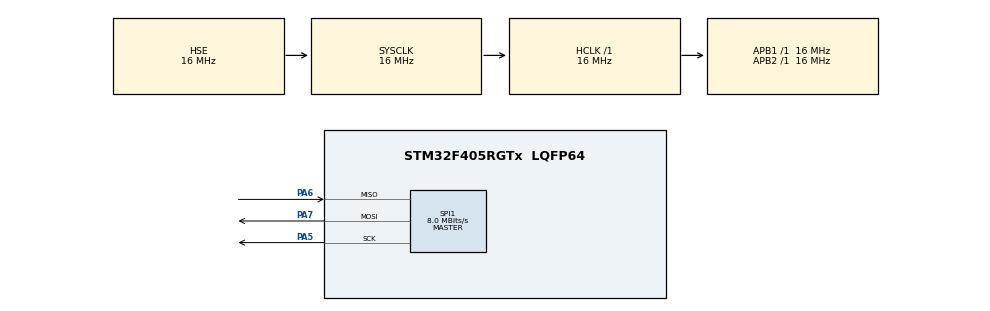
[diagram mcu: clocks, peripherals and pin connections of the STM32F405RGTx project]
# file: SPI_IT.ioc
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Mcu.Family=STM32F4
Mcu.Name=STM32F405RGTx
Mcu.Package=LQFP64
NVIC.PriorityGroup=NVIC_PRIORITYGROUP_4
NVIC.SPI1_IRQn=true\:0\:0\:false\:false\:true\:true\:true\:true
PA13.Mode=Serial_Wire
PA13.Signal=SYS_JTMS-SWDIO
PA14.Mode=Serial_Wire
PA14.Signal=SYS_JTCK-SWCLK
PA5.Mode=Full_Duplex_Master
PA5.Signal=SPI1_SCK
PA6.Mode=Full_Duplex_Master
PA6.Signal=SPI1_MISO
PA7.Mode=Full_Duplex_Master
PA7.Signal=SPI1_MOSI
PH0-OSC_IN.Mode=HSE-External-Oscillator
PH0-OSC_IN.Signal=RCC_OSC_IN
PH1-OSC_OUT.Mode=HSE-External-Oscillator
PH1-OSC_OUT.Signal=RCC_OSC_OUT
ProjectManager.HeapSize=0x200
ProjectManager.StackSize=0x400
ProjectManager.TargetToolchain=MDK-ARM V5.32
RCC.48MHZClocksFreq_Value=48000000
RCC.AHBFreq_Value=16000000
RCC.APB1Freq_Value=16000000
RCC.APB1TimFreq_Value=16000000
RCC.APB2Freq_Value=16000000
RCC.APB2TimFreq_Value=16000000
RCC.CortexFreq_Value=16000000
RCC.HCLKFreq_Value=16000000
RCC.HSE_VALUE=16000000
RCC.HSI_VALUE=16000000
RCC.LSE_VALUE=32768
RCC.PLLSourceVirtual=RCC_PLLSOURCE_HSE
RCC.SYSCLKFreq_VALUE=16000000
RCC.SYSCLKSource=RCC_SYSCLKSOURCE_HSE
RCC.VCOOutputFreq_Value=192000000
SPI1.CalculateBaudRate=8.0 MBits/s
SPI1.Direction=SPI_DIRECTION_2LINES
SPI1.Mode=SPI_MODE_MASTER
SPI1.VirtualType=VM_MASTER
board=custom

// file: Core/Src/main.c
/* USER CODE BEGIN Header */
/**
  ******************************************************************************
  * @file           : main.c
  * @brief          : Main program body
  ******************************************************************************
  * @attention
  *
  * Copyright (c) 2023 STMicroelectronics.
  * All rights reserved.
  *
  * This software is licensed under terms that can be found in the LICENSE file
  * in the root directory of this software component.
  * If no LICENSE file comes with this software, it is provided AS-IS.
  *
  ******************************************************************************
  */
/* USER CODE END Header */
#include "main.h"

SPI_HandleTypeDef hspi1;

/* USER CODE BEGIN PV */
 uint8_t data_in[12]="hello world";
 uint8_t data_out[12];
/* USER CODE END PV */

void SystemClock_Config(void);
static void MX_GPIO_Init(void);
static void MX_SPI1_Init(void);

int main(void)
{

  /* MCU Configuration--------------------------------------------------------*/

  /* Reset of all peripherals, Initializes the Flash interface and the Systick. */
  HAL_Init();

  /* Configure the system clock */
  SystemClock_Config();

  /* Initialize all configured peripherals */
  MX_GPIO_Init();
  MX_SPI1_Init();

  /* Infinite loop */
  while (1)
  {
    HAL_SPI_Transmit_IT(&hspi1,data_in,sizeof(data_in));
	  HAL_SPI_Receive(&hspi1,data_out,sizeof(data_out),1000);
  }
}

void SystemClock_Config(void)
{
  RCC_OscInitTypeDef RCC_OscInitStruct = {0};
  RCC_ClkInitTypeDef RCC_ClkInitStruct = {0};

  /** Configure the main internal regulator output voltage
  */
  __HAL_RCC_PWR_CLK_ENABLE();
  __HAL_PWR_VOLTAGESCALING_CONFIG(PWR_REGULATOR_VOLTAGE_SCALE1);

  /** Initializes the RCC Oscillators according to the specified parameters
  * in the RCC_OscInitTypeDef structure.
  */
  RCC_OscInitStruct.OscillatorType = RCC_OSCILLATORTYPE_HSE;
  RCC_OscInitStruct.HSEState = RCC_HSE_ON;
  RCC_OscInitStruct.PLL.PLLState = RCC_PLL_NONE;
  if (HAL_RCC_OscConfig(&RCC_OscInitStruct) != HAL_OK)
  {
    Error_Handler();
  }

  /** Initializes the CPU, AHB and APB buses clocks
  */
  RCC_ClkInitStruct.ClockType = RCC_CLOCKTYPE_HCLK|RCC_CLOCKTYPE_SYSCLK
                              |RCC_CLOCKTYPE_PCLK1|RCC_CLOCKTYPE_PCLK2;
  RCC_ClkInitStruct.SYSCLKSource = RCC_SYSCLKSOURCE_HSE;
  RCC_ClkInitStruct.AHBCLKDivider = RCC_SYSCLK_DIV1;
  RCC_ClkInitStruct.APB1CLKDivider = RCC_HCLK_DIV1;
  RCC_ClkInitStruct.APB2CLKDivider = RCC_HCLK_DIV1;

  if (HAL_RCC_ClockConfig(&RCC_ClkInitStruct, FLASH_LATENCY_0) != HAL_OK)
  {
    Error_Handler();
  }
}

static void MX_SPI1_Init(void)
{

  /* SPI1 parameter configuration*/
  hspi1.Instance = SPI1;
  hspi1.Init.Mode = SPI_MODE_MASTER;
  hspi1.Init.Direction = SPI_DIRECTION_2LINES;
  hspi1.Init.DataSize = SPI_DATASIZE_8BIT;
  hspi1.Init.CLKPolarity = SPI_POLARITY_LOW;
  hspi1.Init.CLKPhase = SPI_PHASE_1EDGE;
  hspi1.Init.NSS = SPI_NSS_SOFT;
  hspi1.Init.BaudRatePrescaler = SPI_BAUDRATEPRESCALER_2;
  hspi1.Init.FirstBit = SPI_FIRSTBIT_MSB;
  hspi1.Init.TIMode = SPI_TIMODE_DISABLE;
  hspi1.Init.CRCCalculation = SPI_CRCCALCULATION_DISABLE;
  hspi1.Init.CRCPolynomial = 10;
  if (HAL_SPI_Init(&hspi1) != HAL_OK)
  {
    Error_Handler();
  }

}

static void MX_GPIO_Init(void)
{

  /* GPIO Ports Clock Enable */
  __HAL_RCC_GPIOH_CLK_ENABLE();
  __HAL_RCC_GPIOA_CLK_ENABLE();

}

void Error_Handler(void)
{
  __disable_irq();
  while (1)
  {
  }
}
